# DISPC_VP1 register map
Vendor: Texas Instruments
Peripheral module from a debugger description file (folder 66AK2G0x_66AK2G1x).
Registers are 32-bit, access per field, reset 0x0 unless marked. A register's access mark holds for its fields unless they carry their own. Offsets are as the file gives them; lines under a group give offsets from that group; [hi:lo] are bit positions; {n}, {i} and the like mark numbered series; 'fields as' and 'values as' point back to an identical list; <NAME> marks a mode.

## DISPC_VP1
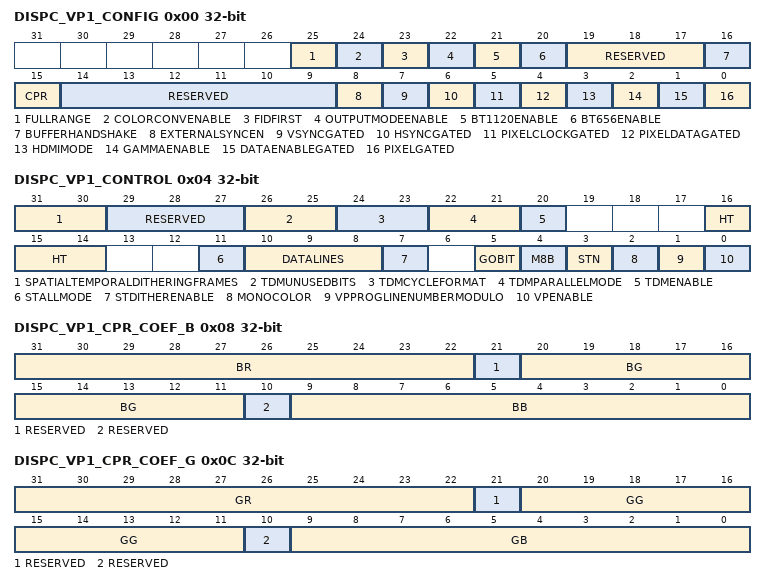
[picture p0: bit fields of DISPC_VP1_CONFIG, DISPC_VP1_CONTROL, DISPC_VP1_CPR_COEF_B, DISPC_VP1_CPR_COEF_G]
0x00 DISPC_VP1_CONFIG
  [25] FULLRANGE rw — Color Space Conversion full range setting. 0h (R/W) = Limited range selected. 1h (R/W) = Full range selected.
  [24] COLORCONVENABLE rw — Enable the color space conversion. It shall be reset when CPR bit-field is set to 0x1. 0h (R/W) = Disable Color Space Conversion RGB to YUV 1h (R/W) = Enable Color Space Conversion RGB to YUV
  [23] FIDFIRST rw — Selects the first field to output in case of interlace mode. In case of progressive mode, the value is not used. 0h (R/W) = First field is even. 1h (R/W) = Odd field is first.
  [22] OUTPUTMODEENABLE rw — Selects between progressive and interlace mode for the VP output. 0h (R/W) = Progressive mode selected. 1h (R/W) = Interlace mode selected.
  [21] BT1120ENABLE rw — Selects BT-1120 format on the VP output. It is not posssible to enable BT656 and BT1120 at the same time on the same VP output. 0h (R/W) = BT-1120 is disabled. 1h (R/W) = BT-1120 is enabled.
  [20] BT656ENABLE rw — Selects BT-656 format on the VP output. It is not posssible to enable BT656 and BT1120 at the same time on the same VP output. 0h (R/W) = BT-656 is disabled. 1h (R/W) = BT-656 is enabled.
  [19:17] RESERVED ro — Write 0's for future compatibility. Reads return 0
  [16] BUFFERHANDSHAKE rw — Controls the handshake between DMA buffer and STALL signal in order to prevent from underflow. The bit shall be set to 0 when the module is not in STALL mode. 0h (R/W) = Only the STALL signal (generated by RFBI) is used regardless of the DMA buffer fullness information in order to provide data to the RFBI module. 1h (R/W) = The STALL signal (generated by RFBI) is used in combination with the DMA buffer fullness information in order to provide data to the RFBI module only when it does not generated buffer underflow.
  [15] CPR rw — Color Phase Rotation Control VP output). It shall be reset when ColorConvEnable bit-field is set to 1. Shadow bit-field. 0h (R/W) = Color Phase Rotation Disabled 1h (R/W) = Color Phase Rotation Enabled
  [14:9] RESERVED ro — Write 0's for future compatibility. Reads return 0
  [8] EXTERNALSYNCEN rw — Selects between external sync and internal sync mode for the VP output. 0h (R/W) = Internal sync mode selected 1h (R/W) = External sync mode selected.
  [7] VSYNCGATED rw — VSYNC Gated Enabled (VP output) Shadow bit-field. 0h (R/W) = VSYNC Gated Disabled 1h (R/W) = VSYNC Gated Enabled
  [6] HSYNCGATED rw — HSYNC Gated Enabled (VP output) Shadow bit-field. 0h (R/W) = HSYNC Gated Disabled 1h (R/W) = HSYNC Gated Enabled
  [5] PIXELCLOCKGATED rw — Pixel Clock Gated Enabled (VP output) Shadow bit-field. 0h (R/W) = Pixel Clock Gated Disabled 1h (R/W) = Pixel Clock Gated Enabled
  [4] PIXELDATAGATED rw — Pixel Data Gated Enabled (VP output) Shadow bit-field. 0h (R/W) = Pixel Data Gated Disabled 1h (R/W) = Pixel Data Gated Enabled
  [3] HDMIMODE rw — Configures the timing generator in HDMI compatible mode to generate same timings as HDMI wrapper timings. 0h (R/W) = Disable HDMI mode. 1h (R/W) = Enable HDMI mode timings: - vertical FSM starts with the VFP period (instead of VSYNC) - last frame ends with the last pixel of data state.
  [2] GAMMAENABLE rw — Enable the gamma Shadow bit-field. 0h (R/W) = Gamma disabled 1h (R/W) = Gamma enabled
  [1] DATAENABLEGATED rw — DE Gated Enable Shadow bit-field. 0h (R/W) = DE signal is not gated 1h (R/W) = DE signal is gated.
  [0] PIXELGATED rw — Pixel Gated Enable Shadow bit-field. 0h (R/W) = Pixel clock always toggles (only in TFT mode) 1h (R/W) = Pixel clock only toggles when there is valid data to display. (only in TFT mode)
0x04 DISPC_VP1_CONTROL
  [31:30] SPATIALTEMPORALDITHERINGFRAMES rw — Spatial/Temporal dithering number of frames for the VP output. Shadow bit-field. 0h (R/W) = Spatial only 1h (R/W) = Spatial and temporal over 2 frames 2h (R/W) = Spatial and temporal over 4 frames 3h (R/W) = Reserved
  [29:27] RESERVED ro — Write 0's for future compatibility. Reads return 0
  [26:25] TDMUNUSEDBITS rw — State of unused bits (TDM mode only) for the VP output. Shadow bit-field. 0h (R/W) = low level (0) 1h (R/W) = high level (1) 2h (R/W) = unchanged from previous state 3h (R/W) = reserved
  [24:23] TDMCYCLEFORMAT rw — Cycle format (TDM mode only) for the VP output. Shadow bit-field. 0h (R/W) = 1 cycle for 1 pixel 1h (R/W) = 2 cycles for 1 pixel 2h (R/W) = 3 cycles for 1 pixel 3h (R/W) = 3 cycles for 2 pixels
  [22:21] TDMPARALLELMODE rw — Output Interface width (TDM mode only) for the VP output. Shadow bit-field. 0h (R/W) = 8-bit parallel output interface selected 1h (R/W) = 9-bit parallel output interface selected 2h (R/W) = 12-bit parallel output interface selected 3h (R/W) = 16-bit parallel output interface selected
  [20] TDMENABLE rw — Enable the multiple cycle format for the VP output. Shadow bit-field. 0h (R/W) = TDM disabled 1h (R/W) = TDM enabled
  [16:14] HT rw — Hold Time for VP output. Shadow bit-field. Encoded value (from 1 to 8) to specify the number of external digital clock periods to hold the data (programmed value = value minus one)
  [11] STALLMODE rw — STALL Mode for the VP output. Shadow bit-field. 0h (R/W) = Normal mode selected 1h (R/W) = STALL mode selected. The Display Controller sends the data without considering the VSYNC/HSYNC. The VP output is disabled at the end of the transfer of the frame. The S/W has to re-enable the VP output in order to generate a new frame.
  [10:8] DATALINES rw — Width of the data bus on VP output. Shadow bit-field. 0h (R/W) = 12-bit output aligned on the LSB of the pixel data interface 1h (R/W) = 16-bit output aligned on the LSB of the pixel data interface 2h (R/W) = 18-bit output aligned on the LSB of the pixel data interface 3h (R/W) = 24-bit output aligned on the LSB of the pixel data interface 4h (R/W) = 30-bit output aligned on the LSB of the pixel data interface 5h (R/W) = 36-bit output aligned on the LSB of the pixel data interface
  [7] STDITHERENABLE rw — Spatial Temporal dithering enable for the VP output Shadow bit-field. 0h (R/W) = Spatial/Temporal dithering logic disabled 1h (R/W) = Spatial/Temporal dithering logic enabled
  [5] GOBIT rw — GO Command for the VP output. It is used to synchronized the pipelines associated with the VP output. wr:immediate 0h (R/W) = The hardware has finished updating the internal shadow registers of the pipeline(s) connected to the VP output using the user values. The hardware resets the bit when the update is completed. 1h (R/W) = The user has finished to program the shadow registers of the pipeline(s) associated with the VP output and the hardware can update the internal registers at the VFP start period
  [4] M8B rw — Mono 8-bit mode of the primary LCD 0h (R/W) = Pixel data [3:0] is used to output four pixel values to the panel at each pixel clock transition. (only in Passive Mono 1h (R/W) = Pixel data [7:0] is used to output eight pixel values to the panel each pixel clock transition. (only in Passive Mono
  [3] STN rw — LCD Display type of the primary LCD 0h (R/W) = Passive or STN display operation disabled. 1h (R/W) = Passive or STN display operation enabled. STN dither logic is enabled.
  [2] MONOCOLOR rw — Monochrome/Color selection for the primary LCD 0h (R/W) = Color operation enabled (STN mode only) 1h (R/W) = Monochrome operation enabled (STN mode only)
  [1] VPPROGLINENUMBERMODULO rw — Enable the modulo of the line number interrupt generation 0h (R/W) = Disable modulo 1h (R/W) = Enable Modulo
  [0] VPENABLE rw — Enable the video port output wr:immediate 0h (R/W) = VP output disabled (at the end of the frame when the bit is reset) 1h (R/W) = VP output enabled
0x08 DISPC_VP1_CPR_COEF_B
  [31:22] BR rw — BR Coefficient Encoded signed value (from -512 to 511).
  [21] RESERVED ro — Write 0's for future compatibility. Reads return 0
  [20:11] BG rw — BG Coefficient Encoded signed value (from -512 to 511).
  [10] RESERVED ro — Write 0's for future compatibility. Reads return 0
  [9:0] BB rw — BB Coefficient Encoded signed value (from -512 to 511).
0x0C DISPC_VP1_CPR_COEF_G
  [31:22] GR rw — GR Coefficient Encoded signed value (from -512 to 511).
  [21] RESERVED ro — Write 0's for future compatibility. Reads return 0
  [20:11] GG rw — GG Coefficient Encoded signed value (from -512 to 511).
  [10] RESERVED ro — Write 0's for future compatibility. Reads return 0
  [9:0] GB rw — GB Coefficient Encoded signed value (from -512 to 511).
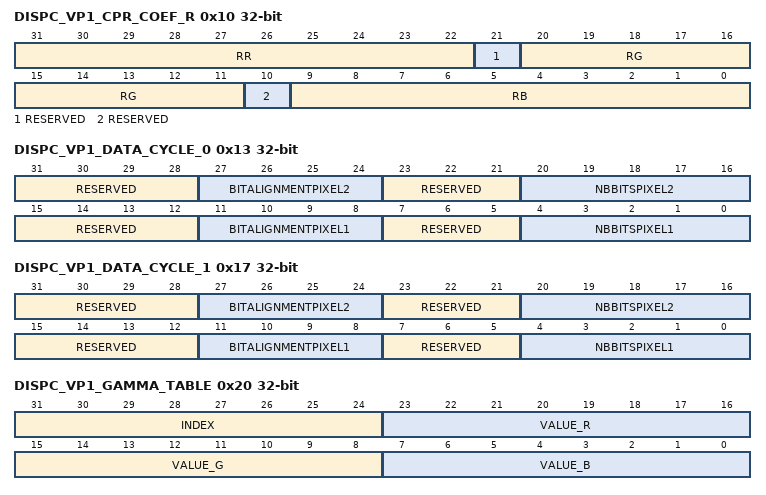
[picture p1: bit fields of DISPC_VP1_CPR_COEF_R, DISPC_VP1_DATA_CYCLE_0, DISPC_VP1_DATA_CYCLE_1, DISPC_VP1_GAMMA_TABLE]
0x10 DISPC_VP1_CPR_COEF_R
  [31:22] RR rw — RR Coefficient Encoded signed value (from -512 to 511).
  [21] RESERVED ro — Write 0's for future compatibility. Reads return 0
  [20:11] RG rw — RG Coefficient Encoded signed value (from -512 to 511).
  [10] RESERVED ro — Write 0's for future compatibility. Reads return 0
  [9:0] RB rw — RB Coefficient Encoded signed value (from -512 to 511).
0x13 DISPC_VP1_DATA_CYCLE_0
  [31:28] RESERVED ro — Write 0's for future compatibility. Reads return 0
  [27:24] BITALIGNMENTPIXEL2 rw — Bit alignment Alignment of the bits from pixel#2 on the output interface
  [23:21] RESERVED ro — Write 0's for future compatibility. Reads return 0
  [20:16] NBBITSPIXEL2 rw — Number of bits Number of bits from the pixel #2 (value from 0 to 16 bits). The values from 17 to 31 are invalid.
  [15:12] RESERVED ro — Write 0's for future compatibility. Reads return 0
  [11:8] BITALIGNMENTPIXEL1 rw — Bit alignment Alignment of the bits from pixel#1 on the output interface
  [7:5] RESERVED ro — Write 0's for future compatibility. Reads return 0
  [4:0] NBBITSPIXEL1 rw — Number of bits Number of bits from the pixel #1 (value from 0 to 16 bits). The values from 17 to 31 are invalid.
0x17 DISPC_VP1_DATA_CYCLE_1
  fields as DISPC_VP1_DATA_CYCLE_0
0x20 DISPC_VP1_GAMMA_TABLE wo
  [31:24] INDEX — Defines the location in the table where the bit-field VALUE is stored
  [23:16] VALUE_R — 8-bit value used to defined the value to be stored in the gamma table
  [15:8] VALUE_G — 8-bit value used to defined the value to be stored in the gamma table
  [7:0] VALUE_B — 8-bit value used to defined the value to be stored in the gamma table
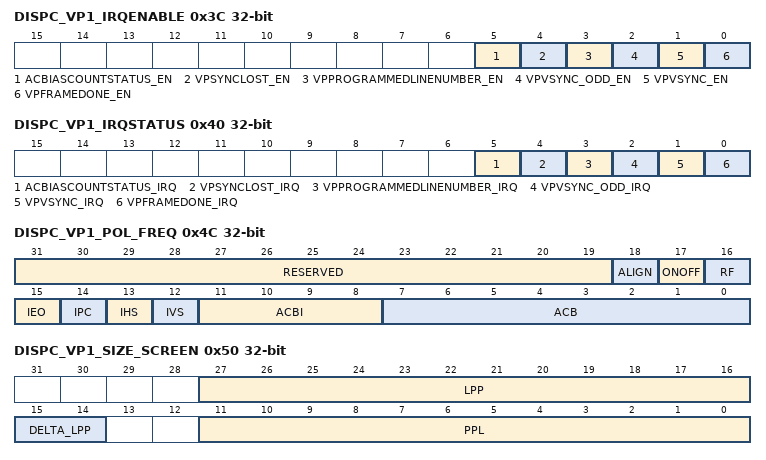
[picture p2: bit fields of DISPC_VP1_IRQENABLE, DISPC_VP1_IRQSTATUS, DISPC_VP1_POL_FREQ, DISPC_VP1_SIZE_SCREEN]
0x3C DISPC_VP1_IRQENABLE
  [5] ACBIASCOUNTSTATUS_EN rw — AC BIAS transition counter has decremented to zero 0h (R/W) = ACBIASCOUNTSTATUS for the primary LCD output is masked 1h (R/W) = ACBIASCOUNTSTATUS for the primary LCD output generates an interrupt when it occurs
  [4] VPSYNCLOST_EN rw — Synchronization Lost for Video Port. 0h (R/W) = SyncLost for the primary VP output is masked 1h (R/W) = SyncLost for the primary VP output generates an interrupt when it occurs
  [3] VPPROGRAMMEDLINENUMBER_EN rw — Programmed Line Number. It indicates that the scan of the display has reached the programmed user line number. 0h (R/W) = ProgrammedLineNumber is masked 1h (R/W) = ProgrammedLineNumber generates an interrupt when it occurs
  [2] VPVSYNC_ODD_EN rw — VSYNC for odd field from interlace mode only. 0h (R/W) = EVSYNC_ODD for the VP output is masked 1h (R/W) = EVSYNC_ODD for the VP output generates an interrupt when it occurs
  [1] VPVSYNC_EN rw — Vertical Synchronization for VP. 0h (R/W) = VSYNC for the primary VP output is masked 1h (R/W) = VSYNC for the primary VP output generates an interrupt when it occurs
  [0] VPFRAMEDONE_EN rw — Frame Done for Video Port. VP output has been disabled by user. All the data have been sent. 0h (R/W) = FrameDone for the primary VP output is masked 1h (R/W) = FrameDone for the primary VP output generates an interrupt when it occurs
0x40 DISPC_VP1_IRQSTATUS access not given
  [5] ACBIASCOUNTSTATUS_IRQ — AC BIAS transition counter has decremented to zero 0h (R/W) = READS: Event is false. WRITES: Status bit unchanged. 1h (R/W) = READS: Event is true (pending). WRITES: Status bit is reset. (access RW1C)
  [4] VPSYNCLOST_IRQ — Synchronization Lost on VP output. The required data are not output at the correct time due to too short blanking periods or stall of at least one pipelines associated with VP output. 0h (R/W) = READS: Event is false. WRITES: Status bit unchanged. 1h (R/W) = READS: Event is true (pending). WRITES: Status bit is reset. (access RW1C)
  [3] VPPROGRAMMEDLINENUMBER_IRQ — Programmed Line Number. It indicates that the scan of the display has reached the programmed user line number. 0h (R/W) = READS: Event is false. WRITES: Status bit unchanged. 1h (R/W) = READS: Event is true (pending). WRITES: Status bit is reset. (access RW1C)
  [2] VPVSYNC_ODD_IRQ — VSYNC for odd field from interlace mode only. 0h (R/W) = READS: Event is false. WRITES: Status bit unchanged. 1h (R/W) = READS: Event is true (pending). WRITES: Status bit is reset. (access RW1C)
  [1] VPVSYNC_IRQ — Vertical Synchronization for VP output. It is used as VSYNC_EVEN in case of interlace mode. 0h (R/W) = READS: Event is false. WRITES: Status bit unchanged. 1h (R/W) = READS: Event is true (pending). WRITES: Status bit is reset. (access RW1C)
  [0] VPFRAMEDONE_IRQ — Frame Done for VP. VP output has been disabled by user. All the data have been sent. 0h (R/W) = READS: Event is false. WRITES: Status bit unchanged. 1h (R/W) = READS: Event is true (pending). WRITES: Status bit is reset. (access RW1C)
0x44 DISPC_VP1_LINE_NUMBER
  [11:0] LINENUMBER rw — Display panel line number programming. Line number defines the line on which the programmable interrupt is generated and the DMA request occurs.
0x4C DISPC_VP1_POL_FREQ
  [31:19] RESERVED ro — Write 0's for future compatibility. Reads return 0
  [18] ALIGN rw — Defines the alignment betwwen HSYNC and VSYNC assertion. 0h (R/W) = VSYNC and HSYNC are not aligned 1h (R/W) = VSYNC and HSYNC assertions are aligned.
  [17] ONOFF rw — HSYNC/VSYNC Pixel clock Control On/Off 0h (R/W) = HSYNC and VSYNC are driven on opposite edges of pixel clock than pixel data 1h (R/W) = HSYNC and VSYNC are driven according to bit 16
  [16] RF rw — Program HSYNC/VSYNC Rise or Fall 0h (R/W) = HSYNC and VSYNC are driven on falling edge of pixel clock (if bit 17 set to 1) 1h (R/W) = HSYNC and VSYNC are driven on rising edge of pixel clock (if bit 17 set to 1)
  [15] IEO rw — Invert output enable 0h (R/W) = Ac-bias is active high (active display mode) 1h (R/W) = Ac-bias is active low (active display mode)
  [14] IPC rw — Invert pixel clock 0h (R/W) = Data is driven on the VP data lines on the rising-edge of the pixel clock 1h (R/W) = Data is driven on the VP data lines on the falling-edge of the pixel clock
  [13] IHS rw — Invert HSYNC 0h (R/W) = Line clock pin is active high and inactive low 1h (R/W) = Line clock pin is active low and inactive high
  [12] IVS rw — Invert VSYNC 0h (R/W) = Frame clock pin is active high and inactive low 1h (R/W) = Frame clock pin is active low and inactive high
  [11:8] ACBI rw — AC Bias Pin transitions per interrupt 0h (R/W) = Line clock pin is active high and inactive low 1h (R/W) = Line clock pin is active low and inactive high
  [7:0] ACB rw — AC Bias Pin Frequency 0h (R/W) = Line clock pin is active high and inactive low 1h (R/W) = Line clock pin is active low and inactive high
0x50 DISPC_VP1_SIZE_SCREEN
  [27:16] LPP rw — Lines per panel Encoded value (from 1 to 4096) to specify the number of lines per panel (program to value minus one).
  [15:14] DELTA_LPP rw — Indicates the delta size value of the odd field compared to the even field 0h (R/W) = same size 1h (R/W) = odd size = even size +1 2h (R/W) = Odd size = even size -1
  [11:0] PPL rw — Pixels per line Encoded value (from 1 to 4096) to specify the number of pixels contains within each line on the display (program to value minus one). In STALL mode, any value is valid. In non STALL mode, only values multiple of 8 pixels are valiid.
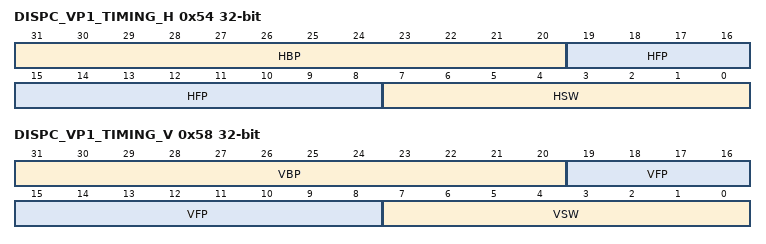
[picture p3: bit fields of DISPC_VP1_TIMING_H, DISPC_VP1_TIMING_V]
0x54 DISPC_VP1_TIMING_H rw
  [31:20] HBP — Horizontal Back Porch. Encoded value (from 1 to 4096) to specify the number of pixel clock periods to add to the beginning of a line transmission before the first set of pixels is output to the displaydisplay (program to value minus one). When in BT mode and interlaced, this field corresponds to the vertical field blanking No 2 for Even Field.
  [19:8] HFP — Horizontal front porch. Encoded value (from 1 to 4096) to specify the number of pixel clock periods to add to the end of a line transmission before line clock is asserted display (program to value minus one). When in BT mode and interlaced, this field corresponds to the vertical field blanking No 1 for Even Field.
  [7:0] HSW — Horizontal synchronization pulse width Encoded value (from 1 to 256) to specify the number of pixel clock periods to pulse the line clock at the end of each line display (program to value minus one). When in BT mode, this field corresponds to the LSB 8-bits of the 12-bit horizontal blanking(BT_HBLANK[11:0]= {VSW[3:0],HSW[7:0]}).
0x58 DISPC_VP1_TIMING_V rw
  [31:20] VBP — Vertical back porch Encoded value (from 0 to 4095) to specify the number of line clock periods to add to the beginning of a frame. When in BT mode and interlaced, this field corresponds to the vertical field blanking No 2 for Odd Field. When in BT and in progressive mode, this field corresponds to the Vertical frame blanking No 2 . before the first set of pixels is output to the display.
  [19:8] VFP — Vertical front porch Encoded value (from 0 to 4095) to specify the number of line clock periods to add to the end of each frame. When in BT mode and interlaced, this field corresponds to the vertical field blanking No 1 for Odd Field. When in BT and in progressive mode, this field corresponds to the Vertical frame blanking No 2 .
  [7:0] VSW — Vertical synchronization pulse width Encoded value (from 1 to 256) to specify the number of line clock periods to pulse the frame clock (VSYNC) pin at the end of each frame after the end of frame wait (VFP) period elapses. Frame clock uses as VSYNC signal in active mode. When in BT mode, the lsb 4-bits of this field (VSW[3:0]) corresponds to the MSB 4-bits of the 12-bit horizontal blanking(BT_HBLANK= {VSW[3:0],HSW[7:0]}).
